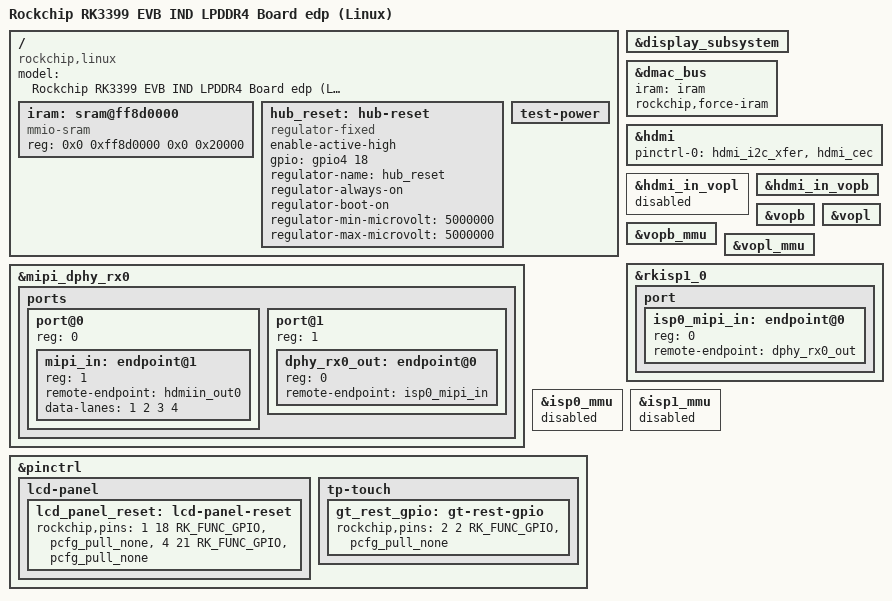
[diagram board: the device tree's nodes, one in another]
// SPDX-License-Identifier: (GPL-2.0+ OR MIT)
/*
 * Copyright (c) 2019-2020 Fuzhou Rockchip Electronics Co., Ltd.
 */

/dts-v1/;

#include "rk3399-evb-ind.dtsi"
#include "rk3399-linux.dtsi"

/ {
	model = "Rockchip RK3399 EVB IND LPDDR4 Board edp (Linux)";
	compatible = "rockchip,linux", "rockchip,rk3399-evb-ind-lpddr4-linux", "rockchip,rk3399";

	iram: sram@ff8d0000 {
		compatible = "mmio-sram";
		reg = <0x0 0xff8d0000 0x0 0x20000>;
	};

	hub_reset: hub-reset {
		compatible = "regulator-fixed";
		enable-active-high;
		gpio = <&gpio4 18 GPIO_ACTIVE_HIGH>;
		regulator-name = "hub_reset";
		regulator-always-on;
		regulator-boot-on;
		regulator-min-microvolt = <5000000>;
		regulator-max-microvolt = <5000000>;
	};

	test-power {
		status = "okay";
	};
};

&display_subsystem {
	status = "okay";
};

&dmac_bus {
	iram = <&iram>;
	rockchip,force-iram;
};

#if 0
&dsi {
	status = "disabled";

	dsi_panel: panel {
		compatible ="simple-panel-dsi";
		reg = <0>;
		//power-supply = <&vcc3v3_lcd>;
		//backlight = <&backlight>;
		
		//pinctrl-names = "default";
		//pinctrl-0 = <&lcdrst>;
		
		//enable-gpios = <&gpio1 3 GPIO_ACTIVE_HIGH>;
		//reset-gpios = <&gpio1 3 GPIO_ACTIVE_LOW>;
		
		dsi,flags = <(MIPI_DSI_MODE_VIDEO | MIPI_DSI_MODE_VIDEO_BURST | MIPI_DSI_MODE_LPM | MIPI_DSI_MODE_EOT_PACKET)>;
		dsi,format = <MIPI_DSI_FMT_RGB888>;
		dsi,lanes = <4>;
        dsi,channel = <0>;

        enable-delay-ms = <35>;
        prepare-delay-ms = <6>;      
        unprepare-delay-ms = <0>;
        disable-delay-ms = <20>;		
		
		panel-init-sequence = [	
			15 78 01 11 
			15 05 01 29 
		];

		panel-exit-sequence = [
			05 64 01 28
			05 96 01 10
		];
	};
};


&vopl_out_dsi {
	status = "disabled";
};
//========kernel dsi0
&dsi_in_vopl {
	status = "disabled";
};

&dsi_in_vopb {
	status = "disabled";
};

&dsi1 {
	status = "disabled";
	rockchip,dual-channel = <&dsi>;
//	rockchip,lane-rate = <528>;
	panel@0 {
		status = "okay";
		compatible = "simple-panel-dsi";
		reg = <0>;
		backlight = <&backlight>;
		//enable-gpios = <&gpio4 29 GPIO_ACTIVE_HIGH>;
		//power-supply = <>;
		//power-supply = <&vcc3v3_lcd>;
		pinctrl-names = "default";
		pinctrl-0 = <&lcd_panel_reset>;
		reset-gpios = <&gpio1 18 GPIO_ACTIVE_HIGH>; //MIPI1_RST 1.8V
		//enable-gpios = <&gpio1 18 GPIO_ACTIVE_HIGH>; //LCD_EN1 GPIO4_A5

		
		prepare-delay-ms = <80>;
		reset-delay-ms = <100>;
		init-delay-ms = <80>;
		disable-delay-ms = <80>;
		unprepare-delay-ms = <80>;
		
		dsi,flags = <(MIPI_DSI_MODE_VIDEO | MIPI_DSI_MODE_VIDEO_BURST |
			      MIPI_DSI_MODE_LPM | MIPI_DSI_MODE_EOT_PACKET)>;
		dsi,format = <MIPI_DSI_FMT_RGB888>;
		dsi,lanes  = <4>;
		
		panel-init-sequence = [
			15 00 02 ee 50
			39 00 03 ea 85 55
			15 00 02 60 00
			15 00 02 64 44
			15 00 02 b4 08 
			15 00 02 9a 10 
			15 00 02 9b a4
			39 00 04 6c 02 07 10
			39 00 03 a1 02 80
			39 00 06 90 00 40 40 44 41
			39 00 04 a5 09 00 00
			15 00 02 81 55
			15 00 02 95 71
			15 00 02 3b 44
			15 00 02 3c 00
			15 00 02 3d 33
			15 00 02 27 00
			15 00 02 28 20
			15 00 02 ee 60
			15 00 02 50 cd
			15 00 02 60 b4
			15 00 02 52 77
			15 00 02 59 26
			15 00 02 61 0f
			15 00 02 62 05
			15 00 02 c0 01
			15 00 02 6a 69
			15 00 02 69 69
			15 00 02 57 3f
			15 00 02 c2 01
			39 00 04 c4 07 33 33
			15 00 02 dc 10
			15 00 02 c3 2f
			15 00 02 c8 1a
			39 00 03 5d 32 14
			39 00 03 da 00 71
			15 00 02 6b 05
			39 00 06 a0 02 1f 25 2b 2a
			39 00 06 80 02 1f 25 2b 2a
			39 00 06 a5 35 2b 3d 1f 1d
			39 00 06 85 35 2b 3d 1f 1d
			39 00 06 aa 1f 05 1b 15 25
			39 00 06 8a 1f 05 1b 15 25
			39 00 05 af 2c 3a 4e 7f
			39 00 05 8f 2c 3a 4e 7f
			15 00 02 ee 80
			39 00 06 00 09 10 00 a5 ad
			39 00 06 05 08 0a 11 00 02
			39 00 06 0a ad 08 10 00 00
			39 00 06 0f 00 00 00 1d 05
			39 00 06 20 10 17 2d a5 ad
			39 00 06 25 08 12 19 00 a5
			39 00 06 2a ad 08 10 00 00
			39 00 06 2f 00 00 00 1d 05
			39 00 06 60 25 24 2d a5 ad
			39 00 06 65 00 00 02 24 25
			39 00 06 6a 2d a5 ad 00 00
			15 00 02 6f 02
			39 00 06 a0 42 32 40 30 34
			39 00 06 a5 44 36 46 00 71
			39 00 06 aa 71 71 71 71 71 
			39 00 06 af 60 e0 71 71 70
			39 00 03 b4 10 71
			39 00 06 c0 43 33 41 31 35
			39 00 06 c5 45 37 47 01 71
			39 00 06 ca 71 71 71 71 71 
			39 00 06 cf 61 e1 71 71 70
			39 00 03 d4 11 71
			15 00 02 ee 00 
			39 00 03 ea 00 00
		
			15 78 01 11 
			15 05 01 29 
			
		];
	};
};

&dsi1_in_vopl {
	status = "disabled";
};

&dsi1_in_vopb {

        status = "disabled";
};

&vopb_out_dsi1{

        status = "disabled";
};

&route_dsi1 {
        status = "disabled";
        connect = <&vopb_out_dsi1>;
};
#endif

&hdmi {
	pinctrl-names = "default";
	pinctrl-0 = <&hdmi_i2c_xfer>, <&hdmi_cec>;
	#address-cells = <1>;
	#size-cells = <0>;
	#sound-dai-cells = <0>;
	status = "okay";
};

&hdmi_in_vopl {
	status = "disabled";
};

&hdmi_in_vopb {
        status = "okay";
};

/*
 * if enable dp_sound, should disable spdif_sound and spdif_out
 */
/*&spdif_out {
	status = "disabled";
};

&spdif_sound {
	status = "disabled";
};*/

&vopb {
	status = "okay";
};

&vopb_mmu {
	status = "okay";
};

&vopl {
	status = "okay";
};

&vopl_mmu {
	status = "okay";
};

&mipi_dphy_rx0 {
       status = "okay";

       ports {
               #address-cells = <1>;
               #size-cells = <0>;

				port@0 {
					reg = <0>;
					#address-cells = <1>;
					#size-cells = <0>;

					mipi_in: endpoint@1 {
						reg = <1>;
						remote-endpoint = <&hdmiin_out0>;
						data-lanes = <1 2 3 4>;
					};
				};

                port@1 {
                       reg = <1>;
                       #address-cells = <1>;
                       #size-cells = <0>;

                       dphy_rx0_out: endpoint@0 {
                               reg = <0>;
                               remote-endpoint = <&isp0_mipi_in>;
                       };
               };
       };
};

&rkisp1_0 {
       status = "okay";

       port {
               #address-cells = <1>;
               #size-cells = <0>;

               isp0_mipi_in: endpoint@0 {
                       reg = <0>;
                       remote-endpoint = <&dphy_rx0_out>;
               };
       };
};

&isp0_mmu {
	status = "disabled";
};

&isp1_mmu {
    status = "disabled";
};

&pinctrl {
		lcd-panel {
		lcd_panel_reset: lcd-panel-reset {
			rockchip,pins = //<3 28 RK_FUNC_GPIO &pcfg_pull_up>; /*Modify by alvin, surport for bl_12v_en pin. GPIO3_D4*/
				<1 18 RK_FUNC_GPIO &pcfg_pull_none>,
				<4 21 RK_FUNC_GPIO &pcfg_pull_none>;
		};
	};
	
	tp-touch {
		gt_rest_gpio: gt-rest-gpio {
			rockchip,pins =
				<2 2 RK_FUNC_GPIO &pcfg_pull_none>;
		};
	};
};

/* DON'T PUT ANYTHING BELOW HERE.  PUT IT ABOVE PINCTRL */
/* DON'T PUT ANYTHING BELOW HERE.  PUT IT ABOVE PINCTRL */
/* DON'T PUT ANYTHING BELOW HERE.  PUT IT ABOVE PINCTRL */

